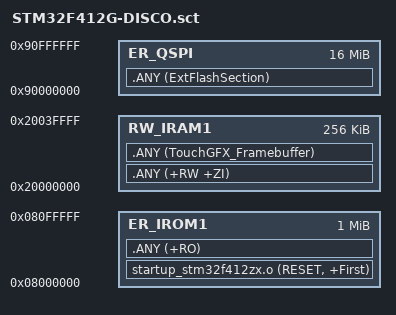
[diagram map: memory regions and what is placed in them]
; *************************************************************
; *** Scatter-Loading Description File generated by uVision ***
; *************************************************************

LR_IROM1 0x08000000 0x00100000  {    ; load region size_region
  ER_IROM1 0x08000000 0x00100000  {  ; load address = execution address
   startup_stm32f412zx.o (RESET, +First)
   .ANY (+RO)
  }
  RW_IRAM1 0x20000000 0x00040000  {  ; RW data - 256KB total RAM
   .ANY (+RW +ZI)
   .ANY (TouchGFX_Framebuffer)
  }
}

LR_QSPI 0x90000000 0x01000000  {    ; load region size_region
  ER_QSPI 0x90000000 0x01000000  {  ; load address = execution address
   .ANY (ExtFlashSection)
;  .ANY (FontFlashSection)
;  .ANY (TextFlashSection)
  }
}
